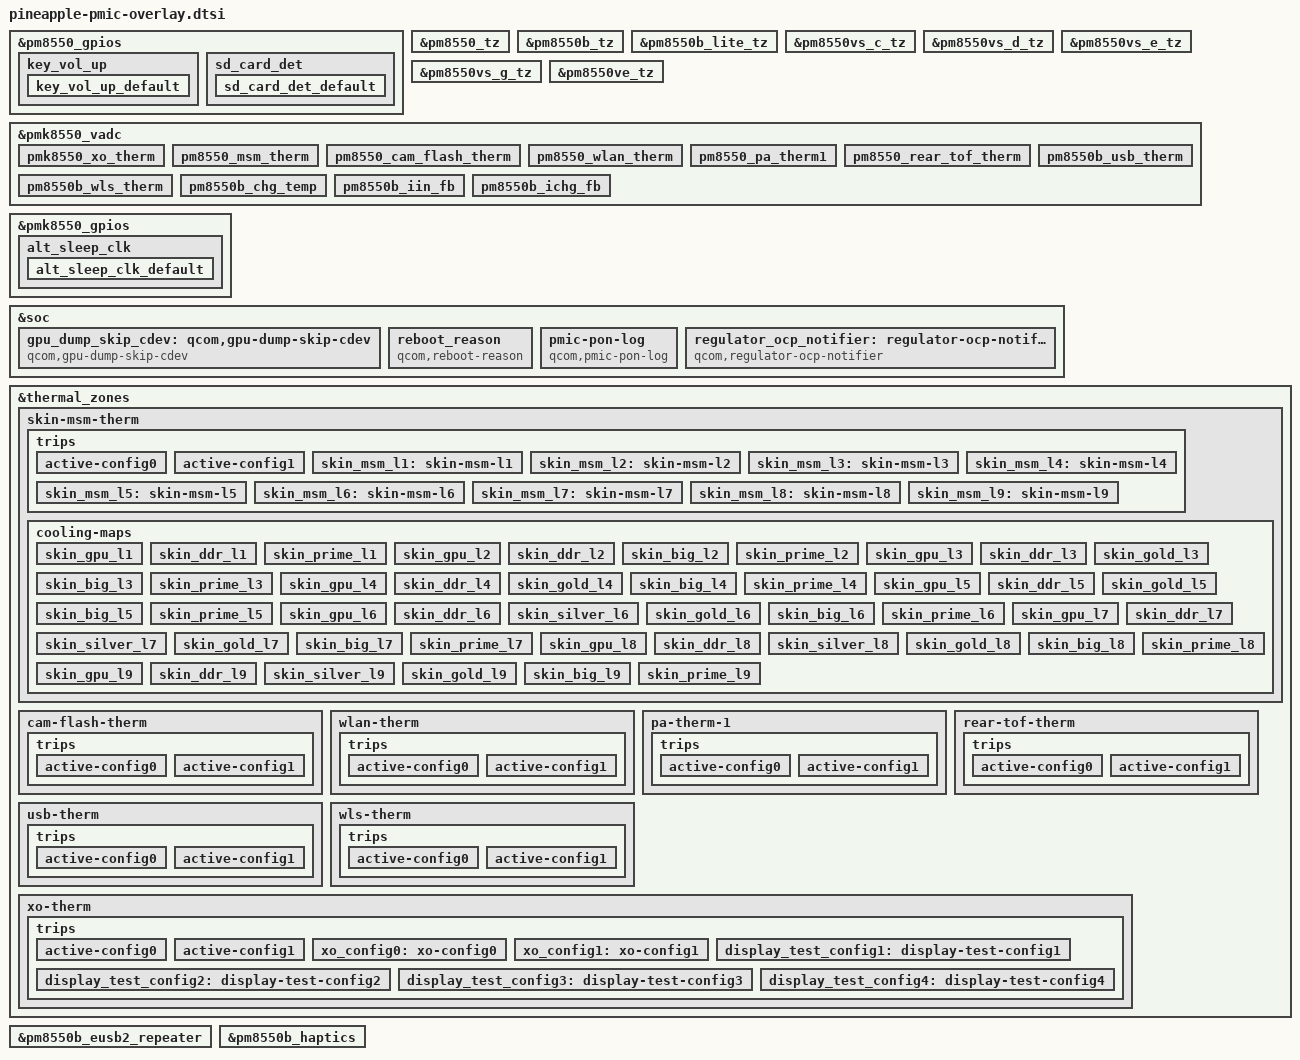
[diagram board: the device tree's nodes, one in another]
#include <dt-bindings/gpio/gpio.h>

#include "pm8010.dtsi"
#include "pm8550.dtsi"
#include "pm8550b.dtsi"
#include "pm8550ve.dtsi"
#include "pm8550vs.dtsi"
#include "pmk8550.dtsi"
#include "pmr735d.dtsi"

&pm8550_gpios {
	key_vol_up {
		key_vol_up_default: key_vol_up_default {
			pins = "gpio6";
			function = "normal";
			input-enable;
			bias-pull-up;
			power-source = <1>;
		};
	};

	sd_card_det {
		sd_card_det_default: sd_card_det_default {
			pins = "gpio12";
			function = "normal";
			input-enable;
			output-disable;
			bias-pull-up;
			power-source = <1>; /* 1.8 V */
		};
	};
};

&pm8550_tz {
	io-channels = <&pmk8550_vadc PM8550_ADC5_GEN3_DIE_TEMP>;
	io-channel-names = "thermal";
};

&pm8550b_tz {
	io-channels = <&pmk8550_vadc PM8550B_ADC5_GEN3_DIE_TEMP>;
	io-channel-names = "thermal";
};

&pm8550b_lite_tz {
	io-channels = <&pmk8550_vadc PM8550B_ADC5_GEN3_TEMP_ALARM_LITE>;
	io-channel-names = "thermal";
};

&pm8550vs_c_tz {
	io-channels = <&pmk8550_vadc PM8550VS_C_ADC5_GEN3_DIE_TEMP>;
	io-channel-names = "thermal";
};

&pm8550vs_d_tz {
	io-channels = <&pmk8550_vadc PM8550VS_D_ADC5_GEN3_DIE_TEMP>;
	io-channel-names = "thermal";
};

&pm8550vs_e_tz {
	io-channels = <&pmk8550_vadc PM8550VS_E_ADC5_GEN3_DIE_TEMP>;
	io-channel-names = "thermal";
};

&pm8550vs_g_tz {
	io-channels = <&pmk8550_vadc PM8550VS_G_ADC5_GEN3_DIE_TEMP>;
	io-channel-names = "thermal";
};

&pm8550ve_tz {
	io-channels = <&pmk8550_vadc PM8550VE_ADC5_GEN3_DIE_TEMP>;
	io-channel-names = "thermal";
};

&pmk8550_vadc {
	pmk8550_xo_therm {
		reg = <PMK8550_ADC5_GEN3_AMUX_THM1_XO_THERM_100K_PU>;
		label = "pmk8550_xo_therm";
		qcom,ratiometric;
		qcom,hw-settle-time = <200>;
		qcom,pre-scaling = <1 1>;
		qcom,adc-tm-type = <1>;
	};

	pm8550_msm_therm {
		reg = <PM8550_ADC5_GEN3_AMUX_THM1_100K_PU>;
		label = "pm8550_msm_therm";
		qcom,ratiometric;
		qcom,hw-settle-time = <200>;
		qcom,pre-scaling = <1 1>;
		qcom,adc-tm-type = <1>;
	};

	pm8550_cam_flash_therm {
		reg = <PM8550_ADC5_GEN3_AMUX_THM2_100K_PU>;
		label = "pm8550_cam_flash_therm";
		qcom,ratiometric;
		qcom,hw-settle-time = <200>;
		qcom,pre-scaling = <1 1>;
		qcom,adc-tm-type = <1>;
	};

	pm8550_wlan_therm {
		reg = <PM8550_ADC5_GEN3_AMUX_THM3_100K_PU>;
		label = "pm8550_wlan_therm";
		qcom,ratiometric;
		qcom,hw-settle-time = <200>;
		qcom,pre-scaling = <1 1>;
		qcom,adc-tm-type = <1>;
	};

	pm8550_pa_therm1 {
		reg = <PM8550_ADC5_GEN3_AMUX_THM4_100K_PU>;
		label = "pm8550_pa_therm_1";
		qcom,ratiometric;
		qcom,hw-settle-time = <200>;
		qcom,pre-scaling = <1 1>;
		qcom,adc-tm-type = <1>;
	};

	pm8550_rear_tof_therm {
		reg = <PM8550_ADC5_GEN3_AMUX_THM5_100K_PU>;
		label = "pm8550_rear_tof_therm";
		qcom,ratiometric;
		qcom,hw-settle-time = <200>;
		qcom,pre-scaling = <1 1>;
		qcom,adc-tm-type = <1>;
	};

	pm8550b_usb_therm {
		reg = <PM8550B_ADC5_GEN3_AMUX_THM4_USB_THERM_100K_PU>;
		label = "pm8550b_usb_therm";
		qcom,ratiometric;
		qcom,hw-settle-time = <200>;
		qcom,pre-scaling = <1 1>;
		qcom,adc-tm-type = <1>;
	};

	pm8550b_wls_therm {
		reg = <PM8550B_ADC5_GEN3_AMUX_THM6_GPIO10_100K_PU>;
		label = "pm8550b_wls_therm";
		qcom,ratiometric;
		qcom,pre-scaling = <1 1>;
		qcom,adc-tm-type = <1>;
	};

	pm8550b_chg_temp {
		reg = <PM8550B_ADC5_GEN3_CHG_TEMP>;
		label = "pm8550b_chg_temp";
	};

	pm8550b_iin_fb {
		reg = <PM8550B_ADC5_GEN3_IIN_FB>;
		label = "pm8550b_iin_fb";
	};

	pm8550b_ichg_fb {
		reg = <PM8550B_ADC5_GEN3_ICHG_FB>;
		label = "pm8550b_ichg_fb";
	};
};

&pmk8550_gpios {
	alt_sleep_clk {
		alt_sleep_clk_default: alt_sleep_clk_default {
			pins = "gpio3";
			function = "func1";
			input-disable;
			output-enable;
			bias-disable;
			power-source = <1>;
		};
	};
};

&soc {
	gpu_dump_skip_cdev: qcom,gpu-dump-skip-cdev {
		compatible = "qcom,gpu-dump-skip-cdev";
		nvmem-cells = <&wr_thermal_flag>;
		nvmem-cell-names = "wr_thermal_flag";
		#cooling-cells = <2>;
	};
};

&thermal_zones {
	skin-msm-therm {
		polling-delay-passive = <250>;
		polling-delay = <1000>;
		thermal-sensors = <&pmk8550_vadc PM8550_ADC5_GEN3_AMUX_THM1_100K_PU>;
		trips {
			active-config0 {
				temperature = <125000>;
				hysteresis = <1000>;
				type = "passive";
			};

			active-config1 {
				temperature = <125000>;
				hysteresis = <1000>;
				type = "passive";
			};

			skin_msm_l1: skin-msm-l1 {
				temperature = <46000>;
				hysteresis = <1000>;
				type = "passive";
			};

			skin_msm_l2: skin-msm-l2 {
				temperature = <47000>;
				hysteresis = <1000>;
				type = "passive";
			};

			skin_msm_l3: skin-msm-l3 {
				temperature = <48000>;
				hysteresis = <1500>;
				type = "passive";
			};

			skin_msm_l4: skin-msm-l4 {
				temperature = <49000>;
				hysteresis = <2500>;
				type = "passive";
			};

			skin_msm_l5: skin-msm-l5 {
				temperature = <51500>;
				hysteresis = <3000>;
				type = "passive";
			};

			skin_msm_l6: skin-msm-l6 {
				temperature = <54000>;
				hysteresis = <3000>;
				type = "passive";
			};

			skin_msm_l7: skin-msm-l7 {
				temperature = <57000>;
				hysteresis = <3000>;
				type = "passive";
			};

			skin_msm_l8: skin-msm-l8 {
				temperature = <60000>;
				hysteresis = <3000>;
				type = "passive";
			};

			skin_msm_l9: skin-msm-l9 {
				temperature = <63000>;
				hysteresis = <3000>;
				type = "passive";
			};
		};

		cooling-maps {
			skin_gpu_l1 {
				trip = <&skin_msm_l1>;
				cooling-device = <&msm_gpu 1 1>;
			};

			skin_ddr_l1 {
				trip = <&skin_msm_l1>;
				cooling-device = <&ddr_cdev 1 1>;
			};

			skin_prime_l1 {
				trip = <&skin_msm_l1>;
				cooling-device = <&cpu_cluster3_cdev 8 8>;
			};

			skin_gpu_l2 {
				trip = <&skin_msm_l2>;
				cooling-device = <&msm_gpu 1 1>;
			};

			skin_ddr_l2 {
				trip = <&skin_msm_l2>;
				cooling-device = <&ddr_cdev 1 1>;
			};

			skin_big_l2 {
				trip = <&skin_msm_l2>;
				cooling-device = <&cpu_cluster2_cdev 4 4>;
			};

			skin_prime_l2 {
				trip = <&skin_msm_l2>;
				cooling-device = <&cpu_cluster3_cdev 8 8>;
			};

			skin_gpu_l3 {
				trip = <&skin_msm_l3>;
				cooling-device = <&msm_gpu 1 1>;
			};

			skin_ddr_l3 {
				trip = <&skin_msm_l3>;
				cooling-device = <&ddr_cdev 2 2>;
			};

			skin_gold_l3 {
				trip = <&skin_msm_l3>;
				cooling-device = <&cpu_cluster1_cdev 8 8>;
			};

			skin_big_l3 {
				trip = <&skin_msm_l3>;
				cooling-device = <&cpu_cluster2_cdev 8 8>;
			};

			skin_prime_l3 {
				trip = <&skin_msm_l3>;
				cooling-device = <&cpu_cluster3_cdev 12 12>;
			};

			skin_gpu_l4 {
				trip = <&skin_msm_l4>;
				cooling-device = <&msm_gpu 2 2>;
			};

			skin_ddr_l4 {
				trip = <&skin_msm_l4>;
				cooling-device = <&ddr_cdev 6 6>;
			};

			skin_gold_l4 {
				trip = <&skin_msm_l4>;
				cooling-device = <&cpu_cluster1_cdev 10 10>;
			};

			skin_big_l4 {
				trip = <&skin_msm_l4>;
				cooling-device = <&cpu_cluster2_cdev 10 10>;
			};

			skin_prime_l4 {
				trip = <&skin_msm_l4>;
				cooling-device = <&cpu_cluster3_cdev 18 18>;
			};

			skin_gpu_l5 {
				trip = <&skin_msm_l5>;
				cooling-device = <&msm_gpu 4 4>;
			};

			skin_ddr_l5 {
				trip = <&skin_msm_l5>;
				cooling-device = <&ddr_cdev 8 8>;
			};

			skin_gold_l5 {
				trip = <&skin_msm_l5>;
				cooling-device = <&cpu_cluster1_cdev 12 12>;
			};

			skin_big_l5 {
				trip = <&skin_msm_l5>;
				cooling-device = <&cpu_cluster2_cdev 18 18>;
			};

			skin_prime_l5 {
				trip = <&skin_msm_l5>;
				cooling-device = <&cpu_cluster3_cdev 24 24>;
			};

			skin_gpu_l6 {
				trip = <&skin_msm_l6>;
				cooling-device = <&msm_gpu 6 6>;
			};

			skin_ddr_l6 {
				trip = <&skin_msm_l6>;
				cooling-device = <&ddr_cdev 7 7>;
			};

			skin_silver_l6 {
				trip = <&skin_msm_l6>;
				cooling-device = <&cpu_cluster0_cdev 1 1>;
			};

			skin_gold_l6 {
				trip = <&skin_msm_l6>;
				cooling-device = <&cpu_cluster1_cdev 16 16>;
			};

			skin_big_l6 {
				trip = <&skin_msm_l6>;
				cooling-device = <&cpu_cluster2_cdev 24 24>;
			};

			skin_prime_l6 {
				trip = <&skin_msm_l6>;
				cooling-device = <&cpu_cluster3_cdev 28 28>;
			};

			skin_gpu_l7 {
				trip = <&skin_msm_l7>;
				cooling-device = <&msm_gpu 6 6>;
			};

			skin_ddr_l7 {
				trip = <&skin_msm_l7>;
				cooling-device = <&ddr_cdev 8 8>;
			};

			skin_silver_l7 {
				trip = <&skin_msm_l7>;
				cooling-device = <&cpu_cluster0_cdev 2 2>;
			};

			skin_gold_l7 {
				trip = <&skin_msm_l7>;
				cooling-device = <&cpu_cluster1_cdev 18 18>;
			};

			skin_big_l7 {
				trip = <&skin_msm_l7>;
				cooling-device = <&cpu_cluster2_cdev 26 26>;
			};

			skin_prime_l7 {
				trip = <&skin_msm_l7>;
				cooling-device = <&cpu_cluster3_cdev 30 30>;
			};

			skin_gpu_l8 {
				trip = <&skin_msm_l8>;
				cooling-device = <&msm_gpu 8 8>;
			};

			skin_ddr_l8 {
				trip = <&skin_msm_l8>;
				cooling-device = <&ddr_cdev 8 8>;
			};

			skin_silver_l8 {
				trip = <&skin_msm_l8>;
				cooling-device = <&cpu_cluster0_cdev 3 3>;
			};

			skin_gold_l8 {
				trip = <&skin_msm_l8>;
				cooling-device = <&cpu_cluster1_cdev 24 24>;
			};

			skin_big_l8 {
				trip = <&skin_msm_l8>;
				cooling-device = <&cpu_cluster2_cdev 28 28>;
			};

			skin_prime_l8 {
				trip = <&skin_msm_l8>;
				cooling-device = <&cpu_cluster3_cdev 32 32>;
			};

			skin_gpu_l9 {
				trip = <&skin_msm_l9>;
				cooling-device = <&msm_gpu 10 10>;
			};

			skin_ddr_l9 {
				trip = <&skin_msm_l9>;
				cooling-device = <&ddr_cdev 8 8>;
			};

			skin_silver_l9 {
				trip = <&skin_msm_l9>;
				cooling-device = <&cpu_cluster0_cdev 4 4>;
			};

			skin_gold_l9 {
				trip = <&skin_msm_l9>;
				cooling-device = <&cpu_cluster1_cdev 30 30>;
			};

			skin_big_l9 {
				trip = <&skin_msm_l9>;
				cooling-device = <&cpu_cluster2_cdev 28 28>;
			};

			skin_prime_l9 {
				trip = <&skin_msm_l9>;
				cooling-device = <&cpu_cluster3_cdev 34 34>;
			};
		};
	};

	cam-flash-therm {
		polling-delay-passive = <0>;
		polling-delay = <0>;
		thermal-sensors = <&pmk8550_vadc PM8550_ADC5_GEN3_AMUX_THM2_100K_PU>;
		trips {
			active-config0 {
				temperature = <125000>;
				hysteresis = <1000>;
				type = "passive";
			};

			active-config1 {
				temperature = <125000>;
				hysteresis = <1000>;
				type = "passive";
			};
		};
	};

	wlan-therm {
		polling-delay-passive = <0>;
		polling-delay = <0>;
		thermal-sensors = <&pmk8550_vadc PM8550_ADC5_GEN3_AMUX_THM3_100K_PU>;
		trips {
			active-config0 {
				temperature = <125000>;
				hysteresis = <1000>;
				type = "passive";
			};

			active-config1 {
				temperature = <125000>;
				hysteresis = <1000>;
				type = "passive";
			};
		};
	};

	pa-therm-1 {
		polling-delay-passive = <0>;
		polling-delay = <0>;
		thermal-sensors = <&pmk8550_vadc PM8550_ADC5_GEN3_AMUX_THM4_100K_PU>;
		trips {
			active-config0 {
				temperature = <125000>;
				hysteresis = <1000>;
				type = "passive";
			};

			active-config1 {
				temperature = <125000>;
				hysteresis = <1000>;
				type = "passive";
			};
		};
	};

	rear-tof-therm {
		polling-delay-passive = <0>;
		polling-delay = <0>;
		thermal-sensors = <&pmk8550_vadc PM8550_ADC5_GEN3_AMUX_THM5_100K_PU>;
		trips {
			active-config0 {
				temperature = <125000>;
				hysteresis = <1000>;
				type = "passive";
			};

			active-config1 {
				temperature = <125000>;
				hysteresis = <1000>;
				type = "passive";
			};
		};
	};

	usb-therm {
		polling-delay-passive = <0>;
		polling-delay = <0>;
		thermal-sensors = <&pmk8550_vadc PM8550B_ADC5_GEN3_AMUX_THM4_USB_THERM_100K_PU>;
		trips {
			active-config0 {
				temperature = <125000>;
				hysteresis = <1000>;
				type = "passive";
			};

			active-config1 {
				temperature = <125000>;
				hysteresis = <1000>;
				type = "passive";
			};
		};
	};

	wls-therm {
		polling-delay-passive = <0>;
		polling-delay = <0>;
		thermal-sensors = <&pmk8550_vadc PM8550B_ADC5_GEN3_AMUX_THM6_GPIO10_100K_PU>;
		trips {
			active-config0 {
				temperature = <125000>;
				hysteresis = <1000>;
				type = "passive";
			};

			active-config1 {
				temperature = <125000>;
				hysteresis = <1000>;
				type = "passive";
			};
		};
	};

	xo-therm {
		polling-delay-passive = <0>;
		polling-delay = <0>;
		thermal-sensors = <&pmk8550_vadc PMK8550_ADC5_GEN3_AMUX_THM1_XO_THERM_100K_PU>;
		trips {
			active-config0 {
				temperature = <125000>;
				hysteresis = <1000>;
				type = "passive";
			};

			active-config1 {
				temperature = <125000>;
				hysteresis = <1000>;
				type = "passive";
			};

			xo_config0: xo-config0 {
				temperature = <78000>;
				hysteresis = <8000>;
				type = "passive";
			};

			xo_config1: xo-config1 {
				temperature = <80000>;
				hysteresis = <10000>;
				type = "passive";
			};

			display_test_config1: display-test-config1 {
				temperature = <125000>;
				hysteresis = <1000>;
				type = "passive";
			};

			display_test_config2: display-test-config2 {
				temperature = <125000>;
				hysteresis = <1000>;
				type = "passive";
			};

			display_test_config3: display-test-config3 {
				temperature = <125000>;
				hysteresis = <1000>;
				type = "passive";
			};

			display_test_config4: display-test-config4 {
				temperature = <125000>;
				hysteresis = <1000>;
				type = "passive";
			};
		};
	};
};

&pm8550b_eusb2_repeater {
	vdd18-supply = <&pm_humu_l15>;
	vdd3-supply = <&pm_humu_l5>;
};

&pm8550b_haptics {
	nvmem-names = "hap_cfg_sdam";
	nvmem = <&pmk8550_sdam_46>;
};

&soc {
	reboot_reason {
		compatible = "qcom,reboot-reason";
		nvmem-cells = <&restart_reason>;
		nvmem-cell-names = "restart_reason";
	};

//#ifndef OPLUS_FEATURE_ESIM
//	DBO3: regulator-dbo3 {
//		compatible = "qti-regulator-fixed";
//		regulator-name = "dbo3";
//		regulator-min-microvolt = <3600000>;
//		regulator-max-microvolt = <3600000>;
//		gpio = <&pm8550_gpios 9 GPIO_ACTIVE_HIGH>;
//		regulator-enable-ramp-delay = <1500>;
//		enable-active-high;
//	};
//#endif /*OPLUS_FEATURE_ESIM*/

	pmic-pon-log {
		compatible = "qcom,pmic-pon-log";
		nvmem = <&pmk8550_sdam_5>, <&pmk8550_sdam_6>;
		nvmem-names = "pon_log0", "pon_log1";
		depends-on-supply = <&gh_watchdog>;
	};

	regulator_ocp_notifier: regulator-ocp-notifier {
		compatible = "qcom,regulator-ocp-notifier";
		interrupt-parent = <&spmi_bus>;
		interrupts = <0x0 0x71 0x1 IRQ_TYPE_EDGE_RISING>,
			     <0x0 0x85 0x1 IRQ_TYPE_EDGE_RISING>;
		nvmem-cells = <&ocp_log>, <&alarm_log>;
		nvmem-cell-names = "ocp_log", "alarm_log";
	};
};
